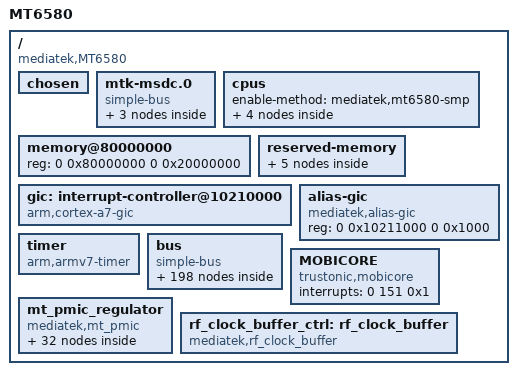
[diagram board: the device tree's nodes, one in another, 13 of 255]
/*
 * Mediatek's MT6580 SoC device tree source
 *
 * Copyright (c) 2013 MediaTek Co., Ltd.
 * http://www.mediatek.com
 *
 */

#include <dt-bindings/interrupt-controller/arm-gic.h>
#include <dt-bindings/interrupt-controller/irq.h>
#include "mt6580-pinfunc.h"
#include <dt-bindings/mmc/mt6580-msdc.h>

/ {
	model = "MT6580";
	compatible = "mediatek,MT6580";
	interrupt-parent = <&gic>;
	#address-cells = <2>;
	#size-cells = <2>;

		/* chosen */
		chosen {
		bootargs = "console=tty0 console=ttyMT0,921600n1 root=/dev/ram initrd=0x84000000,0x400000 loglevel=8";
		};

/* Do not put any bus before mtk-msdc, because it should be mtk-msdc.0 for partition device node usage */
		mtk-msdc.0 {
			compatible = "simple-bus";
			#address-cells = <1>;
			#size-cells = <1>;
			ranges = <0 0 0 0xffffffff>;

			mmc0: msdc0@11120000 {
				compatible = "mediatek,mt6580-mmc";
				reg = <0x11120000 0x10000/*MSDC0_BASE*/
					0x10001e84 0x2>;/*FPGA PWR_GPIO,PWR_GPIO_EO*/
				interrupts = <GIC_SPI 38 IRQ_TYPE_LEVEL_LOW>;
				status = "disabled";
				/* peter check when rainier ccf ready
				clocks = <&perisys PERI_MSDC30_0>,
					 <&topckgen TOP_MUX_MSDC30_0>,
					 <&topckgen TOP_MSDCPLL_CK>,
					 <&topckgen TOP_MSDCPLL_D2>,
					 <&topckgen TOP_MSDCPLL_D4>;
				clock-names="MSDC0-CLOCK",
					"MSDC0_PLL_SEL",
					"MSDC0_PLL_800M",
					"MSDC0_PLL_400M",
					"MSDC0_PLL_200M"; */
			};

			mmc1: msdc1@11130000 {
				compatible = "mediatek,mt6580-mmc";
				reg = <0x11130000 0x10000/*MSDC1_BASE*/
					0x10001e84 0x2>;/*FPGA PWR_GPIO,PWR_GPIO_EO*/
				interrupts = <GIC_SPI 39 IRQ_TYPE_LEVEL_LOW>;
				cd-gpios = <&pio 3 0>;
				status = "disabled";
				/* peter check when rainier ccf ready
				clocks = <&perisys PERI_MSDC30_1>;
				clock-names="MSDC1-CLOCK"; */
			};

			msdc1_ins: default {
				compatible = "mediatek,msdc1_ins-eint";
			};
		};

		cpus {
			#address-cells = <1>;
			#size-cells = <0>;
			enable-method = "mediatek,mt6580-smp";

			cpu0: cpu@0 {
				device_type = "cpu";
				compatible = "arm,cortex-a7";
				reg = <0x000>;
				clock-frequency = <1700000000>;
			};

			cpu1: cpu@1 {
				device_type = "cpu";
				compatible = "arm,cortex-a7";
				reg = <0x001>;
				clock-frequency = <1700000000>;
			};

			cpu2: cpu@2 {
				device_type = "cpu";
				compatible = "arm,cortex-a7";
				reg = <0x002>;
				clock-frequency = <1700000000>;
			};

			cpu3: cpu@3 {
				device_type = "cpu";
				compatible = "arm,cortex-a7";
				reg = <0x003>;
				clock-frequency = <1700000000>;
			};
		};

		memory@80000000 {
				device_type = "memory";
				reg = <0 0x80000000 0 0x20000000>;
		};

		reserved-memory {
				#address-cells = <2>;
				#size-cells = <2>;
				ranges;
				consys-reserve-memory {
					compatible = "mediatek,consys-reserve-memory";
					no-map;
					size = <0 0x200000>;
					alignment = <0 0x200000>;
				};
				reserve-memory-ccci_md1 {
						compatible = "mediatek,reserve-memory-ccci_md1";
						no-map;
						size = <0 0x1800000>; /* MD ROM + RAM + SMEM */
						alignment = <0 0x2000000>; /* 32M alignment */
						alloc-ranges = <0 0x80000000 0 0x80000000>;
				};

				pstore-reserved-memory@83f10000 {
						compatible = "mediatek,pstore";
						reg = <0 0x83f10000 0 0xe0000>;
				};

				ram_console-reserved-memory@83f00000 {
						compatible = "mediatek,ram_console";
						reg = <0 0x83f00000 0 0x10000>;
				};

				minirdump-reserved-memory@83ff0000 {
						compatible = "mediatek, minirdump";
						reg = <0 0x83ff0000 0 0x10000>;
				};
		};

		gic: interrupt-controller@10210000 {
				compatible = "arm,cortex-a7-gic";
				#interrupt-cells = <3>;
				#address-cells = <0>;
				interrupt-controller;
				reg = <0 0x10211000 0 0x1000>,
							<0 0x10212000 0 0x1000>,
							<0 0x10200100 0 0x1000>;
			 interrupts = <1 9 0xf04>;
		};

		/* redundent gic device node to support other module's
			who want to use same query flow to get basic GIC info.
			EX: eint might want to know max GIC nr by */
		alias-gic {
			compatible = "mediatek,alias-gic";
			reg = <0 0x10211000 0 0x1000>; /* only dist base is enough */
		};

		timer {
				compatible = "arm,armv7-timer";
				interrupts = <1 13 0x8>,
				<1 14 0x8>,
				<1 11 0x8>,
				<1 10 0x8>;
				clock-frequency = <13000000>;
		};

	bus {
		compatible = "simple-bus";
		#address-cells = <1>;
		#size-cells = <1>;
		ranges = <0 0 0 0xffffffff>;

		chipid@08000000 {
			compatible = "mediatek,chipid";
			reg = <0x08000000 0x0004>,
					<0x08000004 0x0004>,
					<0x08000008 0x0004>,
					<0x0800000C 0x0004>;
		};

		TOPCKGEN@0x10000000 {
			compatible = "mediatek,TOPCKGEN";
			reg = <0x10000000 0x1000>;
		};

		INFRACFG_AO@0x10001000 {
			compatible = "mediatek,INFRACFG_AO";
			reg = <0x10001000 0x1000>;
		};

		bat_meter: bat_meter {
			compatible = "mediatek,bat_meter";
		};

		BAT_NOTIFY {
			compatible = "mediatek,bat_notify";
		};

		bat_comm: bat_comm {
			compatible = "mediatek,battery";
		};

		keypad: keypad@10002000 {
			compatible = "mediatek,mt6580-keypad";
			reg = <0x10002000 0x1000>;
			interrupts = <0 109 0x2>;
		};

		PERICFG@0x10003000 {
			compatible = "mediatek,PERICFG";
			reg = <0x10003000 0x1000>;
		};

		RESERVED@0x10004000 {
			compatible = "mediatek,RESERVED";
			reg = <0x10004000 0x1000>;
		};

		gpio_usage_mapping:gpio {
			compatible = "mediatek,gpio_usage_mapping";
		};

		gpio: gpio@0x10005000 {
			compatible = "mediatek,gpio";
			reg = <0x10005000 0x1000>;
		};

		SLEEP@0x10006000 {
			compatible = "mediatek,SLEEP";
			reg = <0x10006000 0x1000>;
			interrupts = <0 88 0x8>,
						 <0 89 0x8>,
						 <0 90 0x8>,
						 <0 91 0x8>;
		};

		TOPRGU@0x10007000 {
			compatible = "mediatek,TOPRGU";
			reg = <0x10007000 0x1000>;
			interrupts = <0 157 0x2>;
		};

		APXGPT@0x10008000 {
			compatible = "mediatek,APXGPT";
			reg = <0x10008000 0x1000>;
			interrupts = <0 92 0x8>;
			clock-frequency = <13000000>;
		};

		EFUSEC@0x10009000 {
			compatible = "mediatek,EFUSEC";
			reg = <0x10009000 0x1000>;
		};

		hacc@0x1000A000 {
			compatible = "mediatek,hacc";
			reg = <0x1000A000 0x1000>;
			interrupts = <0 110 0x0>;
		};

		cpu_dbgapb: cpu_dbgapb@10170000 {
			compatible = "mediatek,mt6580-dbg_debug";
			num = <4>;
			reg = <0x10170000 0x2000
				0x10172000 0x2000
				0x10174000 0x2000
				0x10176000 0x2000>;
		};

		eintc: eintc@1000b000 {
			compatible = "mediatek,mt-eic";
			reg = <0x1000B000 0x1000>;
			interrupts = <GIC_SPI 94 IRQ_TYPE_LEVEL_HIGH>;

			#interrupt-cells = <2>;
			interrupt-controller;

			mediatek,max_eint_num = <26>;
			mediatek,mapping_table_entry = <83>;
			mediatek,mapping_table = <0 0>, /* <gpio_pin, eint_pin> */
					<1 1>,
					<2 2>,
					<3 3>,
					<4 4>,
					<5 5>,
					<6 6>,
					<7 7>,
					<8 8>,
					<9 9>,
					<10 10>,
					<11 11>,
					<12 12>,
					<13 13>,
					<14 14>,
					<15 15>,
					<16 0>,
					<17 1>,
					<18 2>,
					<19 3>,
					<20 4>,
					<21 5>,
					<22 6>,
					<23 7>,
					<24 8>,
					<25 9>,
					<26 10>,
					<27 11>,
					<28 12>,
					<29 13>,
					<30 14>,
					<31 15>,
					<32 0>,
					<33 1>,
					<34 2>,
					<35 3>,
					<36 4>,
					<37 5>,
					<38 6>,
					<39 7>,
					<40 8>,
					<41 9>,
					<42 10>,
					<43 11>,
					<44 12>,
					<45 13>,
					<46 14>,
					<47 15>,
					<48 0>,
					<49 1>,
					<50 2>,
					<51 3>,
					<52 3>,
					<53 4>,
					<54 5>,
					<55 6>,
					<56 7>,
					<57 8>,
					<58 10>,
					<59 11>,
					<60 12>,
					<61 13>,
					<62 14>,
					<63 15>,
					<64 0>,
					<65 1>,
					<66 2>,
					<67 3>,
					<68 16>,
					<69 4>,
					<70 5>,
					<71 6>,
					<72 7>,
					<73 8>,
					<74 9>,
					<75 10>,
					<76 11>,
					<77 12>,
					<78 13>,
					<81 0>,
					<82 1>,
					<83 2>,
					<84 3>;

			/* the number of gpio/eint mapping might be affected by built-in eint */
			mediatek,builtin_entry = <11>;
			/* gpio, built-in func mode, built-in eint */
			mediatek,builtin_mapping = <0 3 20>, /* USB IDDIG & USB VBUS */
						 <1 3 18>,
						 <7 4 20>,
						 <8 4 18>,
						 <9 3 20>,
						 <10 3 18>,
						 <24 5 20>,
						 <25 5 18>,
						 <77 2 20>,
						 <78 2 18>,
						 <13 1 17>; /* PMIC */
		};

		ap_ccif0:ap_ccif0@1000C000 {
			compatible = "mediatek,ap_ccif0";
			reg =	<0x1000C000 0x1000>,	/*AP_CCIF_BASE*/
				<0x1000D000 0x1000>;	/*MD_CCIF_BASE*/
			interrupts =	<GIC_SPI 93 IRQ_TYPE_LEVEL_LOW>, /* CCIF0 IRQ */
					<GIC_SPI 152 IRQ_TYPE_EDGE_FALLING>;/* MD WDT IRQ */
			mediatek,ccif_capability = <2>;
			mediatek,md_smem_size = <0x200000>; /* md share memory size */
		};

		MCUSYS_CFGREG@0x1020000 {
			compatible = "mediatek,MCUSYS_CFGREG_BASE";
			reg = <0x1020000 0x200>;
		};

		mcucfg: mcucfg@10200000 {
			compatible = "mediatek,mt6580-mcucfg";
			reg = <0x10200000 0x200>;
		};

		AES@0x1000E000 {
			compatible = "mediatek,AES";
			reg = <0x1000E000 0x1000>;
		};

		PWRAP@0x1000F000 {
			compatible = "mediatek,PWRAP";
			reg = <0x1000F000 0x1000>;
			interrupts = <0 108 0x0>;
		};

		DEVAPC_AO@0x10010000 {
			compatible = "mediatek,DEVAPC_AO";
			reg = <0x10010000 0x1000>;
		};

		MIPI_CONFG@0x10011000 {
			compatible = "mediatek,MIPI_CONFG";
			reg = <0x10011000 0x1000>;
		};

		INFRA_MBIST@0x10012000 {
			compatible = "mediatek,INFRA_MBIST";
			reg = <0x10012000 0x1000>;
		};

		RESERVED@0x10013000 {
			compatible = "mediatek,RESERVED";
			reg = <0x10013000 0x1000>;
		};

		IOCFG_T@0x10014000 {
			compatible = "mediatek,IOCFG_T";
			reg = <0x10014000 0x1000>;
		};

		IOCFG_B@0x10015000 {
			compatible = "mediatek,IOCFG_B";
			reg = <0x10015000 0x1000>;
		};

		IOCFG_L@0x10016000 {
			compatible = "mediatek,IOCFG_L";
			reg = <0x10016000 0x1000>;
		};

		IOCFG_R@0x10017000 {
			compatible = "mediatek,IOCFG_R";
			reg = <0x10017000 0x1000>;
		};

		APMIXED@0x10018000 {
			compatible = "mediatek,APMIXED";
			reg = <0x10018000 0x1000>;
		};

		MCUCFG@0x10200000 {
			compatible = "mediatek,MCUCFG";
			reg = <0x10200000 0x1000>;
		};

		INFRACFG@0x10201000 {
			compatible = "mediatek,INFRACFG";
			reg = <0x10201000 0x1000>;
		};

		sys_cirq: sys_cirq@10202000 {
			compatible = "mediatek,mt6580-sys_cirq", "mediatek,mt6735-sys_cirq";
			reg = <0x10202000 0x1000>;
			interrupts = <GIC_SPI 158 IRQ_TYPE_LEVEL_LOW>;
			mediatek,cirq_num = <126>;
			mediatek,spi_start_offset = <32>;
		};


		m4u@10203000 {
			cell-index = <0>;
			compatible = "mediatek,m4u";
			reg = <0x10203000 0x1000>;
			interrupts =  <GIC_SPI 81 IRQ_TYPE_LEVEL_LOW>;
		};

		DEVAPC@0x10204000 {
			compatible = "mediatek,DEVAPC";
			reg = <0x10204000 0x1000>;
			interrupts = <0 74 0x8>;
		};

		EMI@0x10205000 {
			compatible = "mediatek,EMI";
			reg = <0x10205000 0x1000>;
			interrupts = <0 76 0x4>;
		};

		DRAMC_NAO@0x10206000 {
			compatible = "mediatek,DRAMC_NAO";
			reg = <0x10206000 0x1000>;
		};

		DRAMC0@0x10207000 {
			compatible = "mediatek,DRAMC0";
			reg = <0x10207000 0x1000>;
		};

		DDRPHY@0x10208000 {
			compatible = "mediatek,DDRPHY";
			reg = <0x10208000 0x1000>;
		};

		SRAMROM@0x10209000 {
			compatible = "mediatek,SRAMROM";
			reg = <0x10209000 0x1000>;
		};

		gce@1020a000 {
			compatible = "mediatek,gce";
			reg = <0x1020a000 0x1000>;
			interrupts = <GIC_SPI 85 IRQ_TYPE_LEVEL_LOW>,
						<GIC_SPI 86 IRQ_TYPE_LEVEL_LOW>;
			disp_mutex_reg = <0x14015000 0x1000>;
			g3d_config_base = <0x13000000 0 0xffff0000>;
			mmsys_config_base = <0x14000000 1 0xffff0000>;
			disp_dither_base = <0x14010000 2 0xffff0000>;
			mm_na_base = <0x14020000 3 0xffff0000>;
			imgsys_base = <0x15000000 4 0xffff0000>;
			vdec_gcon_base = <0x16000000 5 0xffff0000>;
			venc_gcon_base = <0x17000000 6 0xffff0000>;
			conn_peri_base = <0x18000000 7 0xffff0000>;
			topckgen_base = <0x10000000 8 0xffff0000>;
			kp_base = <0x10010000 9 0xffff0000>;
			scp_sram_base = <0x10020000 10 0xffff0000>;
			infra_na3_base = <0x10030000 11 0xffff0000>;
			infra_na4_base = <0x10040000 12 0xffff0000>;
			scp_base = <0x10050000 13 0xffff0000>;
			mcucfg_base = <0x10200000 14 0xffff0000>;
			gcpu_base = <0x10210000 15 0xffff0000>;
			usb0_base = <0x11200000 16 0xffff0000>;
			usb_sif_base = <0x11210000 17 0xffff0000>;
			audio_base = <0x11220000 18 0xffff0000>;
			msdc0_base = <0x11230000 19 0xffff0000>;
			msdc1_base = <0x11240000 20 0xffff0000>;
			msdc2_base = <0x11250000 21 0xffff0000>;
			msdc3_base = <0x11260000 22 0xffff0000>;
			pwm_sw_base = <0x1100F000 99 0xfffff000>;
			mdp_rdma0_sof = <0>;
			mdp_rsz0_sof = <1>;
			mdp_rsz1_sof = <2>;
			mdp_tdshp_sof = <3>;
			mdp_wdma_sof = <4>;
			mdp_wrot_sof = <5>;
			disp_ovl0_sof = <6>;
			disp_rdma0_sof = <8>;
			disp_wdma0_sof = <10>;
			disp_color_sof = <12>;
			disp_aal_sof = <13>;
			disp_gamma_sof = <14>;
			disp_dither_sof = <15>;
			disp_pwm0_sof = <17>;
			mdp_rdma0_frame_done = <18>;
			mdp_rsz0_frame_done = <19>;
			mdp_rsz1_frame_done = <20>;
			mdp_tdshp_frame_done = <21>;
			mdp_wdma_frame_done = <22>;
			mdp_wrot_write_frame_done = <23>;
			mdp_wrot_read_frame_done = <24>;
			disp_ovl0_frame_done = <25>;
			disp_rdma0_frame_done = <27>;
			disp_wdma0_frame_done = <29>;
			disp_color_frame_done = <31>;
			disp_aal_frame_done = <32>;
			disp_gamma_frame_done = <33>;
			disp_dither_frame_done = <34>;
			disp_dsi0_frame_done = <37>;
			stream_done_0 = <38>;
			stream_done_1 = <39>;
			stream_done_2 = <40>;
			stream_done_3 = <41>;
			stream_done_4 = <42>;
			stream_done_5 = <43>;
			stream_done_6 = <44>;
			stream_done_7 = <45>;
			stream_done_8 = <46>;
			stream_done_9 = <47>;
			buf_underrun_event_0 = <48>;
			dsi0_te_event = <50>;
			isp_frame_done_p2_1 = <66>;
			isp_frame_done_p2_0 = <67>;
			seninf_cam0_fifo_full = <73>;
			apxgpt2_count = <0x10008028>;
		};

		bus_dbg@1020b000 {
			compatible = "mediatek,bus_dbg-v2";
			reg = <0x1020b000 0x1000>;
			interrupts = <GIC_SPI 73 IRQ_TYPE_LEVEL_LOW>;
			two_stage_timeout = <1>;
		};

		TRNG@0x1020C000 {
			compatible = "mediatek,TRNG";
			reg = <0x1020C000 0x1000>;
			interrupts = <0 87 0x8>;
		};

		MCUCFG_BIU@0x1020D000 {
			compatible = "mediatek,MCUCFG_BIU";
			reg = <0x1020D000 0x1000>;
		};


		DBGSYS_DEM@0x1011A000 {
			compatible = "mediatek,DBGSYS_DEM";
			reg = <0x1011A000 0x1000>;
		};

		DBGSYS_CTI@0x10112000 {
			compatible = "mediatek,DBGSYS_CTI";
			reg = <0x10112000 0x1000>;
		};

		DBGSYS_DAPROM@0x10110000 {
			compatible = "mediatek,DBGSYS_DAPROM";
			reg = <0x10110000 0x1000>;
		};

		DBGSYS_CPU@0x10160000 {
			compatible = "mediatek,DBGSYS_CPU";
			reg = <0x10160000 0x20000>;
		};

		DBGSYS_MDSYS@0x10120000 {
			compatible = "mediatek,DBGSYS_MDSYS";
			reg = <0x10120000 0x10000>;
		};

		ap_dma: dma@0x11000000 {
			compatible = "mediatek,ap_dma";
			reg = <0x11000000 0x1000>;
			interrupts = <GIC_SPI 48 IRQ_TYPE_LEVEL_LOW>;
		};

		NFI@0x11001000 {
			compatible = "mediatek,NFI";
			reg = <0x11001000 0x1000>;
			interrupts = <0 47 0x8>;
		};

		NFIECC@0x11002000 {
			compatible = "mediatek,NFIECC";
			reg = <0x11002000 0x1000>;
			interrupts = <0 46 0x8>;
		};

		auxadc: adc_hw@11003000 {
			compatible = "mediatek,mt6735-auxadc";
			reg = <0x11003000 0x1000>;
			interrupts = <GIC_SPI 35 IRQ_TYPE_EDGE_FALLING>;
		};

		FHCTL@0x11004000 {
			compatible = "mediatek,FHCTL";
			reg = <0x11004000 0x1000>;
		};

		AP_UART0@0x11005000 {
			cell-index = <0>;
			compatible = "mediatek,AP_UART0";
			reg = <0x11005000 0x1000>;
			interrupts = <0 44 0x8>;
		};

		AP_UART1@0x11006000 {
			cell-index = <1>;
			compatible = "mediatek,AP_UART1";
			reg = <0x11006000 0x1000>;
			interrupts = <0 45 0x8>;
		};

		AP_DMA_UART0_TX@0x11000480 {
			compatible = "mediatek,AP_DMA_UART0_TX";
			reg = <0x11000480 0x80>;
			interrupts = <0 56 0x8>;
		};

		AP_DMA_UART0_RX@0x11000500 {
			compatible = "mediatek,AP_DMA_UART0_RX";
			reg = <0x11000500 0x80>;
			interrupts = <0 57 0x8>;
		};

				AP_DMA_UART1_TX@0x11000580 {
						compatible = "mediatek,AP_DMA_UART1_TX";
						reg = <0x11000580 0x80>;
						interrupts = <0 58 0x8>;
				};

				AP_DMA_UART1_RX@0x11000600 {
						compatible = "mediatek,AP_DMA_UART1_RX";
						reg = <0x11000600 0x80>;
						interrupts = <0 59 0x8>;
				};


		PWM@0x11008000 {
			compatible = "mediatek,PWM";
			reg = <0x11008000 0x1000>;
			interrupts = <0 36 0x8>;
		};

		syscfg_pctl_a: syscfg_pctl_a@0x10005000 {
			compatible = "mediatek,mt6580-pctl-a-syscfg", "syscon";
			reg = <0x10211000 0x1000>;
		};

		pio: pinctrl@0x10005000 {
			compatible = "mediatek,mt6580-pinctrl";
			reg = <0x10005000 0x1000>;
			mediatek,pctl-regmap = <&syscfg_pctl_a>;
			pins-are-numbered;
			gpio-controller;
			#gpio-cells = <2>;
		};
		i2c0: i2c@11009000 {
			compatible = "mediatek,mt6580-i2c", "mediatek,i2c0";
			cell-index = <0>;
			reg = <0x11009000 0x1000>;
			interrupts = <GIC_SPI 40 IRQ_TYPE_LEVEL_LOW>,
				     <GIC_SPI 50 IRQ_TYPE_LEVEL_LOW>;
			clock-div = <10>;
			#address-cells = <1>;
			#size-cells = <0>;
		};

		i2c1: i2c@1100a000 {
			compatible = "mediatek,mt6580-i2c", "mediatek,i2c1";
			cell-index = <1>;
			reg = <0x1100a000 0x1000>;
			interrupts = <GIC_SPI 41 IRQ_TYPE_LEVEL_LOW>,
				     <GIC_SPI 51 IRQ_TYPE_LEVEL_LOW>;
			clock-div = <10>;
			#address-cells = <1>;
			#size-cells = <0>;
		};

		i2c2: i2c@1100b000 {
			compatible = "mediatek,mt6580-i2c", "mediatek,i2c2";
			cell-index = <2>;
			reg = <0x1100b000 0x1000>;
			interrupts = <GIC_SPI 42 IRQ_TYPE_LEVEL_LOW>,
				     <GIC_SPI 52 IRQ_TYPE_LEVEL_LOW>;
			clock-div = <10>;
			#address-cells = <1>;
			#size-cells = <0>;
		};

		touch: touch@0 {
			compatible = "mediatek,mt6580-touch";
			vtouch-supply = <&mt_pmic_vgp1_ldo_reg>;
		};
		accdet: accdet {
			compatible = "mediatek,mt6580-accdet";
		};

		gse_1: gse_1 {
			compatible = "mediatek, gse_1-eint";
			status = "disabled";
		};

		spi@1100c000 {
			compatible = "mediatek,mt6580-spi";
			cell-index = <0>;
			reg = <0x1100c000 0x1000>;
			interrupts = <GIC_SPI 64 IRQ_TYPE_LEVEL_LOW>;
			mediatek,spi-padmacro = <0>;
		};

		THERM_CTRL@0x1100D000 {
			compatible = "mediatek,THERM_CTRL";
			reg = <0x1100D000 0x1000>;
			interrupts = <0 37 0x8>;
		};


		btif_tx:btif_tx@11000380 {
			compatible = "mediatek,btif_tx";
			reg = <0x11000380 0x80>;
			interrupts = <GIC_SPI 54 IRQ_TYPE_LEVEL_LOW>;
		};

		btif_rx:btif_rx@11000400 {
			compatible = "mediatek,btif_rx";
			reg = <0x11000400 0x80>;
			interrupts = <GIC_SPI 55 IRQ_TYPE_LEVEL_LOW>;
		};

		btif:btif@1100e000 {
			compatible = "mediatek,btif";
			reg = <0x1100e000 0x1000>;
			interrupts = <GIC_SPI 67 IRQ_TYPE_LEVEL_LOW>;
			/*clocks = <&perisys PERI_BTIF>,<&perisys PERI_APDMA>;*/
			/*clock-names = "btifc","apdmac";*/
		};/* End of btif */

		mt3326-gps@0xffffffff {
			compatible = "mediatek,mt3326-gps";
		};


		BTCVSD@0x18000000 {
			compatible = "mediatek,audio_bt_cvsd";
		/*INFRA MISC, conn_bt_cvsd_mask, cvsd_mcu_read, write, packet_indicator*/
			offset =<0xC00 0x2 0xFD0 0xFD4 0xFD8>;
			reg=<0x10001000 0x1000>, /*AUDIO_INFRA_BASE_PHYSICAL*/
						<0x18000000 0x10000>, /*PKV_PHYSICAL_BASE*/
						<0x18080000 0x8000>; /*SRAM_BANK2*/
			interrupts = <0 153 0x8>;
		};

		consys:consys@18070000 {
			compatible = "mediatek,mt6580-consys";
			reg =	<0x18070000 0x0200>,	/*CONN_MCU_CONFIG_BASE*/
				<0x10007000 0x0100>,	/*AP_RGU_BASE*/
				<0x10000000 0x2000>,	/*TOPCKGEN_BASE*/
				<0x10006000 0x1000>,	/*SPM_BASE*/
				<0x10005000 0x1000>;	/*DA_XOBUF*/
			interrupts = <GIC_SPI 154 IRQ_TYPE_LEVEL_LOW>, /*BGF_EINT*/
					<GIC_SPI 156 IRQ_TYPE_LEVEL_LOW>; /*WDT_EINT*/
			/*clocks = <&scpsys SCP_SYS_CONN>,<&infrasys INFRA_CONNMCU_BUS>;*/
			/*clock-names = "conn","bus";*/
			vcn18-supply = <&mt_pmic_vcn_1v8_ldo_reg>;
			vcn28-supply = <&mt_pmic_vcn28_ldo_reg>;
			vcn33_bt-supply = <&mt_pmic_vcn33_bt_ldo_reg>;
			vcn33_wifi-supply = <&mt_pmic_vcn33_wifi_ldo_reg>;
		};

		WIFI@0x180F0000 {
			compatible = "mediatek,WIFI";
			reg = <0x180F0000 0x005C>;
			interrupts = <0 155 0x8>;
		};
		DISP_PWM@0x1100F000 {
			compatible = "mediatek,DISP_PWM";
			reg = <0x1100F000 0x1000>;
			interrupts = <0 33 0x8>;
		};

		usb0:USB0@0x11100000 {
			compatible = "mediatek,USB0";
			cell-index = <0>;
			reg = <0x11100000 0x10000>,
						<0x11110000 0x10000>;
			interrupts = <0 32 0x8>;
			mode = <2>;
			multipoint = <1>;
			dyn_fifo = <1>;
			soft_con = <1>;
			dma = <1>;
			num_eps = <16>;
			dma_channels = <8>;
			iddig_gpio = <9 3>;
			drvvbus_gpio = <10 3>;
			usbiddig:usbiddig {
				compatible = "mediatek,usb_iddig_eint";
			};
		};

		usbphy0: usbphy@0 {
			compatible = "usb-nop-xceiv";
		};

		audio@11140000 {
			compatible = "mediatek,audio";
			reg = <0x11140000 0x10000>;
			interrupts = <0 80 0x8>;
		};

		audgpio:mt_soc_dl1_pcm@11140000 {
			compatible = "mediatek,mt_soc_pcm_dl1";
			reg = <0x11140000 0x1000>;
			interrupts = <0 80 0x8>;
			audclk-gpio = <26 0>;
			audmiso-gpio = <28 0>;
			audmosi-gpio = <27 0>;
		};

		mt_soc_ul1_PCM@11140000 {
			compatible = "mediatek,mt_soc_pcm_capture";
		};

		mt_soc_voice_md1@11140000 {
			compatible = "mediatek,mt_soc_pcm_voice_md1";
		};

		mt_soc_hdmi_pcm@11140000 {
			compatible = "mediatek,mt_soc_pcm_hdmi";
		};

		mt_soc_uldlloopback_pcm@11140000 {
			compatible = "mediatek,mt_soc_pcm_uldlloopback";
		};

		mt_soc_i2s0_pcm@11140000 {
			compatible = "mediatek,mt_soc_pcm_dl1_i2s0";
		};

		mt_soc_mrgrx_pcm@11140000 {
			compatible = "mediatek,mt_soc_pcm_mrgrx";
		};

		mt_soc_mrgrx_awb_pcm@11140000 {
			compatible = "mediatek,mt_soc_pcm_mrgrx_awb";
		};

		mt_soc_fm_i2s_pcm@0x11140000 {
			compatible = "mediatek,mt_soc_pcm_fm_i2s";
		};

		mt_soc_fm_i2s_awb_pcm@11140000 {
			compatible = "mediatek,mt_soc_pcm_fm_i2s_awb";
		};

		mt_soc_i2s0dl1_pcm@11140000 {
			compatible = "mediatek,mt_soc_pcm_dl1_i2s0Dl1";
		};

		mt_soc_dl1_awb_pcm@11140000 {
			compatible = "mediatek,mt_soc_pcm_dl1_awb";
		};

		mt_soc_voice_md1_bt@11140000 {
			compatible = "mediatek,mt_soc_pcm_voice_md1_bt";
		};

		mt_soc_voip_bt_out@11140000 {
			compatible = "mediatek,mt_soc_pcm_dl1_bt";
		};

		mt_soc_voip_bt_in@11140000 {
			compatible = "mediatek,mt_soc_pcm_bt_dai";
		};

		mt_soc_tdmrx_pcm@11140000 {
			compatible = "mediatek,mt_soc_tdm_capture";
		};

		mt_soc_fm_mrgtx_pcm@11140000 {
			compatible = "mediatek,mt_soc_pcm_fmtx";
		};

		mt_soc_ul2_pcm@11140000 {
			compatible = "mediatek,mt_soc_pcm_capture2";
		};

		mt_soc_i2s0_awb_pcm@11140000 {
			compatible = "mediatek,mt_soc_pcm_i2s0_awb";
		};

		mt_soc_voice_md2@11140000 {
			compatible = "mediatek,mt_soc_pcm_voice_md2";
		};

		mt_soc_routing_pcm@11140000 {
			compatible = "mediatek,mt_soc_pcm_routing";
		};

		mt_soc_voice_md2_bt@11140000 {
			compatible = "mediatek,mt_soc_pcm_voice_md2_bt";
		};

		mt_soc_hp_impedance_pcm@11140000 {
			compatible = "mediatek,Mt_soc_pcm_hp_impedance";
		};

		mt_soc_codec_name@11140000 {
			compatible = "mediatek,mt_soc_codec_63xx";
		};

		mt_soc_dummy_pcm@11140000 {
			compatible = "mediatek,mt_soc_pcm_dummy";
		};

		mt_soc_codec_dummy_name@11140000 {
			compatible = "mediatek,mt_soc_codec_dummy";
		};

		mt_soc_routing_dai_name@11140000 {
			compatible = "mediatek,mt_soc_dai_routing";
		};

		mt_soc_dai_name@11140000 {
			compatible = "mediatek,mt_soc_dai_stub";
		};

		mt_soc_dl2_pcm@11140000 {
			compatible = "mediatek,mt_soc_pcm_dl2";
		};

		AHB_MOM@0x11150000 {
			compatible = "mediatek,AHB_MOM";
			reg = <0x11150000 0x10000>;
		};

		MDI@0x11160000 {
			compatible = "mediatek,MDI";
			reg = <0x11160000 0x10000>;
		};

		G3D_CONFIG@0x13000000 {
			compatible = "mediatek,G3D_CONFIG";
			reg = <0x13000000 0x1000>;
		};

		MALI@0x13010000 {
			compatible = "mediatek,MALI";
			reg = <0x13010000 0x10000>;
		};

		mmsys_config@14000000 {
			compatible = "mediatek,mmsys_config";
			reg = <0x14000000 0x1000>;
			interrupts = <GIC_SPI 132 IRQ_TYPE_LEVEL_LOW>;
		};

		mdp_rdma@14001000 {
			compatible = "mediatek,mdp_rdma";
			reg = <0x14001000 0x1000>;
			interrupts = <GIC_SPI 113 IRQ_TYPE_LEVEL_LOW>;
		};

		mdp_rsz0@14002000 {
			compatible = "mediatek,mdp_rsz0";
			reg = <0x14002000 0x1000>;
			interrupts = <GIC_SPI 114 IRQ_TYPE_LEVEL_LOW>;
		};

		mdp_rsz1@14003000 {
			compatible = "mediatek,mdp_rsz1";
			reg = <0x14003000 0x1000>;
			interrupts = <GIC_SPI 115 IRQ_TYPE_LEVEL_LOW>;
		};

		mdp_wdma@14004000 {
			compatible = "mediatek,mdp_wdma";
			reg = <0x14004000 0x1000>;
			interrupts = <GIC_SPI 117 IRQ_TYPE_LEVEL_LOW>;
		};

		mdp_wrot@14005000 {
			compatible = "mediatek,mdp_wrot";
			reg = <0x14005000 0x1000>;
			interrupts = <GIC_SPI 118 IRQ_TYPE_LEVEL_LOW>;
		};

		mdp_tdshp@14006000 {
			compatible = "mediatek,mdp_tdshp";
			reg = <0x14006000 0x1000>;
			interrupts = <GIC_SPI 116 IRQ_TYPE_LEVEL_LOW>;
		};

		lcm: lcm {
			compatible = "mediatek,mt6580-lcm";
		};

		DISPSYS@0x14007000 {
			compatible = "mediatek,DISPSYS";
			reg = <0x14000000 0x1000>,/*DISP_SYS */
			<0x14007000 0x1000>,	/*DISP_OVL0*/
			<0x14008000 0x1000>,	/*DISP_OVL1*/
			<0x14009000 0x1000>,	/*DISP_RDMA0*/
			<0x1400A000 0x1000>,	/*DISP_RDMA1*/
			<0x1400B000 0x1000>,	/*DISP_WDMA0*/
			<0x1400C000 0x1000>,	/*DISP_COLOR*/
			<0x1400D000 0x1000>,	/*DISP_CCORR*/
			<0x1400E000 0x1000>,	/*DISP_AAL*/
			<0x1400F000 0x1000>,	/*DISP_GAMMA*/
			<0x14010000 0x1000>,	/*DISP_DITHER*/
			<0x14011000 0x1000>,	/*DISP_UFOE*/
			<0x14012000 0x1000>,	/*DISP_DSI0*/
			<0x14013000 0x1000>,	/*DISP_DPI0*/
			<0x1100F000 0x1000>,	/*DISP_PWM*/
			<0x14015000 0x1000>,	/*DISP_MUTEX*/
			<0x14016000 0x1000>,	/*DISP_SMI_LARB0 */
			<0x14017000 0x1000>,	/*DISP_SMI_COMMOM*/
			<0x14018000 0x1000>;	/*MIPITX0,real chip would use this*/

			interrupts = <0 0 8>, /*DISP_SYS */
									<0 119 8>, /*DISP_OVL0 */
									<0 0 8>, /*DISP_OVL1 */
									<0 121 8>, /*DISP_RDMA0 */
									<0 0 8>, /*DISP_RDMA1 */
									<0 123 8>, /*DISP_WDMA0 */
									<0 124 8>, /*DISP_COLOR */
									<0 0 8>, /*DISP_CCORR */
									<0 126 8>, /*DISP_AAL */
									<0 127 8>, /*DISP_GAMMA */
									<0 128 8>, /*DISP_DITHER */
									<0 0 8>, /*DISP_UFOE */
									<0 130 8>, /*DISP_DSI0 */
									<0 0 8>, /*DISP_DPI0 */
									<0 0 8>, /*DISP_PWM */
									<0 112 8>, /*DISP_MUTEX */
									<0 0 8>, /*DISP_SMI_LARB0 */
									<0 0 8>, /*DISP_SMI_COMMOM*/
									<0 0 8>; /*MIPITX0*/
					};

		DISP_OVL0@0x14007000 {
			compatible = "mediatek,DISP_OVL0";
			reg = <0x14007000 0x1000>;
			interrupts = <0 119 0x8>;
		};

		DISP_OVL1@0x14008000 {
			compatible = "mediatek,DISP_OVL1";
			reg = <0x14008000 0x1000>;
		};

		DISP_RDMA0@0x14009000 {
			compatible = "mediatek,DISP_RDMA0";
			reg = <0x14009000 0x1000>;
			interrupts = <0 121 0x8>;
		};

		DISP_RDMA1@0x1400A000 {
			compatible = "mediatek,DISP_RDMA1";
			reg = <0x1400A000 0x1000>;
		};

		DISP_WDMA@0x1400B000 {
			compatible = "mediatek,DISP_WDMA";
			reg = <0x1400B000 0x1000>;
			interrupts = <0 123 0x8>;
		};

		DISP_COLOR@0x1400C000 {
			compatible = "mediatek,DISP_COLOR";
			reg = <0x1400C000 0x1000>;
			interrupts = <0 124 0x8>;
		};

		DISP_CCORR@0x1400D000 {
			compatible = "mediatek,DISP_CCORR";
			reg = <0x1400D000 0x1000>;
		};

		DISP_AAL@0x1400E000 {
			compatible = "mediatek,DISP_AAL";
			reg = <0x1400E000 0x1000>;
			interrupts = <0 126 0x8>;
		};

		DISP_GAMMA@0x1400F000 {
			compatible = "mediatek,DISP_GAMMA";
			reg = <0x1400F000 0x1000>;
			interrupts = <0 127 0x8>;
		};

		DISP_DITHER@0x14010000 {
			compatible = "mediatek,DISP_DITHER";
			reg = <0x14010000 0x1000>;
			interrupts = <0 128 0x8>;
		};

		DISP_UFOE@0x14011000 {
			compatible = "mediatek,DISP_UFOE";
			reg = <0x14011000 0x1000>;
		};

		DSI@0x14012000 {
			compatible = "mediatek,DSI";
			reg = <0x14012000 0x1000>;
		};

		DPI@0x14013000 {
			compatible = "mediatek,DPI";
			reg = <0x14013000 0x1000>;
		};


		PTP_FSM@0x1100D000 {
			compatible = "mediatek,PTP_FSM";
			reg = <0x1100D000 0x1000>;
			interrupts = <0 43 0x8>;
		};

		MM_MUTEX@0x14015000 {
			compatible = "mediatek,MM_MUTEX";
			reg = <0x14015000 0x1000>;
			interrupts = <0 112 0x8>;
		};

		SMI_LARB0@0x14016000 {
			compatible = "mediatek,SMI_LARB0";
			reg = <0x14016000 0x1000>;
			interrupts = <0 133 0x8>;
		};

		SMI_COMMON@0x14017000 {
			compatible = "mediatek,SMI_COMMON";
			reg = <0x14017000 0x1000>,/* SMI_COMMON */
				<0x14016000 0x1000>,/* LARB 0 */
				<0x15001000 0x1000>;/* LARB 1 */
		};

		MIPI_TX_CONFIG@0x14018000 {
			compatible = "mediatek,MIPI_TX_CONFIG";
			reg = <0x14018000 0x1000>;
		};

		ISPSYS@0x15000000 {
			compatible = "mediatek,ISPSYS";
			reg = <0x15004000 0x9000>,	/*ISP_ADDR*/
				<0x15000000 0x10000>,	/*IMGSYS_CONFIG_ADDR*/
				<0x10011000 0x4000>,	/*MIPI_ANA_ADDR*/
				<0x10017000 0x1000>;
			interrupts = <0 142 0x8>, /* SENINF */
				<0 139 0x8>; /* CAM0 */
		};
		/*for sysram dev and pipemgr dev*/
		ISP_SYSR@0x15000000 {
			compatible = "mediatek,ISP_SYSR";
		};
		ISP_PIPEM@0x15000000 {
			compatible = "mediatek,ISP_PIPEM";
		};
		kd_camera_hw1:kd_camera_hw1@15008000 {
			compatible = "mediatek,camera_hw";
			reg = <0x15008000 0x1000>;  /* SENINF_ADDR */
			vcama-supply = <&mt_pmic_vcama_ldo_reg>;
			vcamd-supply = <&mt_pmic_vcamd_ldo_reg>;
			vcamaf-supply = <&mt_pmic_vcamaf_ldo_reg>;
			vcamio-supply = <&mt_pmic_vcamio_ldo_reg>;

		};
		kd_camera_hw2:kd_camera_hw2@15008000 {
			compatible = "mediatek,camera_hw2";
			reg = <0x15008000 0x1000>;  /* SENINF_ADDR */
		};
		seninf_top@15008000 {
			compatible = "mediatek,SENINF_TOP";
			reg = <0x15008000 0x1000>;
			interrupts = <0 142 0x8>;
		};

		CAM_0@0x15004000 {
			compatible = "mediatek,CAM_0";
			reg = <0x15004000 0x1000>;
			interrupts = <0 139 0x8>;
		};

		CAM_1@0x15005000 {
			compatible = "mediatek,CAM_1";
			reg = <0x15005000 0x1000>;
		};

		VENC@0x15009000 {
			compatible = "mediatek,VENC";
			reg = <0x15009000 0x1000>;
			interrupts = <0 138 0x8>;
		};

		VDEC@0x1500B000 {
			compatible = "mediatek,VDEC";
			reg = <0x1500B000 0x1000>;
			interrupts = <0 137 0x8>;
		};

		SMI_LARB1@0x15001000 {
			compatible = "mediatek,SMI_LARB1";
			reg = <0x15001000 0x1000>;
			interrupts = <0 136 0x8>;
		};

		IMGSYS_CONFIG@0x15000000 {
			compatible = "mediatek,IMGSYS_CONFIG";
			reg = <0x15000000 0x1000>;
		};

		hwmsensor@0 {
			compatible = "mediatek,hwmsensor";
		};
		gsensor@0 {
			compatible = "mediatek,gsensor";
		};
		alsps:als_ps@0 {
			compatible = "mediatek,als_ps";
		};
		m_acc_pl@0 {
			compatible = "mediatek,m_acc_pl";
		};
		m_alsps_pl@0 {
			compatible = "mediatek,m_alsps_pl";
		};
		sensorHub@0 {
			compatible = "mediatek,sensorHub";
		};
		shf@0 {
			compatible = "mediatek,shf";
		};
		m_batch_pl@0 {
			compatible = "mediatek,m_batch_pl";
		};
		gyro:gyroscope@0 {
			compatible = "mediatek,gyroscope";
		};
		m_gyro_pl@0 {
			compatible = "mediatek,m_gyro_pl";
		};
		barometer@0 {
			compatible = "mediatek,barometer";
		};
		m_baro_pl@0 {
			compatible = "mediatek,m_baro_pl";
		};
		msensor@0 {
			compatible = "mediatek,msensor";
		};
		m_mag_pl@0 {
			compatible = "mediatek,m_mag_pl";
		};
		orientation@0 {
			compatible = "mediatek,orientation";
		};
		pedometer@0 {
			compatible = "mediatek,pedometer";
		};
		m_pdr_pl@0 {
			compatible = "mediatek,m_pdr_pl";
		};
		step_counter@0 {
			compatible = "mediatek,step_counter";
		};
		m_step_c_pl@0 {
			compatible = "mediatek,m_step_c_pl";
		};
		in_pocket@0 {
			compatible = "mediatek,in_pocket";
		};
		m_inpk_pl@0 {
			compatible = "mediatek,m_inpk_pl";
		};
		shake@0 {
			compatible = "mediatek,shake";
		};
		m_shk_pl@0 {
			compatible = "mediatek,m_shk_pl";
		};
		face_down@0 {
			compatible = "mediatek,face_down";
		};
		m_fdn_pl@0 {
			compatible = "mediatek,m_fdn_pl";
		};
		activity@0 {
			compatible = "mediatek,activity";
		};
		m_act_pl@0 {
			compatible = "mediatek,m_act_pl";
		};
		heart_rate@0 {
			compatible = "mediatek,heart_rate";
		};
		m_hrm_pl@0 {
			compatible = "mediatek,m_hrm_pl";
		};
		tilt_detector@0 {
			compatible = "mediatek,tilt_detector";
		};
		m_tilt_pl@0 {
			compatible = "mediatek,m_tilt_pl";
		};
		wake_gesture@0 {
			compatible = "mediatek,wake_gesture";
		};
		m_wag_pl@0 {
			compatible = "mediatek,m_wag_pl";
		};
		glance_gesture@0 {
			compatible = "mediatek,glance_gesture";
		};
		m_glg_pl@0 {
			compatible = "mediatek,m_glg_pl";
		};
		pick_up@0 {
			compatible = "mediatek,pick_up";
		};
		m_pkup_pl@0 {
			compatible = "mediatek,m_pkup_pl";
		};
		als: als {
			compatible = "mediatek, als-eint";
		};

		mtkfb: mtkfb@0 {
			compatible = "mediatek,mtkfb";
		};

		dsi_te: dsi_te {
			compatible = "mediatek, dsi_te-eint";
		};

	};

	MOBICORE {
		compatible = "trustonic,mobicore";
		interrupts = <0 151 0x1>;
	};
	mt_pmic_regulator {
		compatible = "mediatek,mt_pmic";
		buck_regulators {
			compatible = "mediatek,mt_pmic_buck_regulators";
			mt_pmic_vpa_buck_reg: buck_vpa {
				regulator-name = "vpa";
				regulator-min-microvolt = <500000>;
				regulator-max-microvolt = <3650000>;
				regulator-ramp-delay = <50000>;
				regulator-enable-ramp-delay = <180>;
			};
			mt_pmic_vproc_buck_reg: buck_vproc {
				regulator-name = "vproc";
				regulator-min-microvolt = <700000>;
				regulator-max-microvolt = <1493750>;
				regulator-ramp-delay = <6250>;
				regulator-enable-ramp-delay = <180>;
				regulator-always-on;
				regulator-boot-on;
			};
		};	/* End of buck_regulators */
		ldo_regulators {
			compatible = "mediatek,mt_pmic_ldo_regulators";
			mt_pmic_vcn28_ldo_reg: ldo_vcn28 {
				regulator-name = "vcn28";
				regulator-min-microvolt = <1800000>;
				regulator-max-microvolt = <2800000>;
				regulator-enable-ramp-delay = <264>;
			};
			mt_pmic_vtcxo_ldo_reg: ldo_vtcxo {
				regulator-name = "vtcxo";
				regulator-min-microvolt = <2200000>;
				regulator-max-microvolt = <2200000>;
				regulator-enable-ramp-delay = <110>;
			};
			mt_pmic_va_ldo_reg: ldo_va {
				regulator-name = "va";
				regulator-min-microvolt = <1800000>;
				regulator-max-microvolt = <2500000>;
				regulator-enable-ramp-delay = <110>;
			};
			mt_pmic_vcama_ldo_reg: ldo_vcama {
				regulator-name = "vcama";
				regulator-min-microvolt = <1500000>;
				regulator-max-microvolt = <2800000>;
				regulator-enable-ramp-delay = <264>;
			};
			mt_pmic_vcn33_bt_ldo_reg: ldo_vcn33_bt {
				regulator-name = "vcn33_bt";
				regulator-min-microvolt = <3300000>;
				regulator-max-microvolt = <3600000>;
				regulator-enable-ramp-delay = <264>;
			};
			mt_pmic_vcn33_wifi_ldo_reg: ldo_vcn33_wifi {
				regulator-name = "vcn33_wifi";
				regulator-min-microvolt = <3300000>;
				regulator-max-microvolt = <3600000>;
				regulator-enable-ramp-delay = <264>;
			};
			mt_pmic_vio28_ldo_reg: ldo_vio28 {
				regulator-name = "vio28";
				regulator-min-microvolt = <2800000>;
				regulator-max-microvolt = <2800000>;
				regulator-enable-ramp-delay = <264>;
				regulator-boot-on;
			};
			mt_pmic_vsim1_ldo_reg: ldo_vsim1 {
				regulator-name = "vsim1";
				regulator-min-microvolt = <1800000>;
				regulator-max-microvolt = <3000000>;
				regulator-enable-ramp-delay = <264>;
			};
			mt_pmic_vsim2_ldo_reg: ldo_vsim2 {
				regulator-name = "vsim2";
				regulator-min-microvolt = <1800000>;
				regulator-max-microvolt = <3000000>;
				regulator-enable-ramp-delay = <264>;
			};
			mt_pmic_vusb_ldo_reg: ldo_vusb {
				regulator-name = "vusb";
				regulator-min-microvolt = <3300000>;
				regulator-max-microvolt = <3300000>;
				regulator-enable-ramp-delay = <264>;
				regulator-boot-on;
			};
			mt_pmic_vgp1_ldo_reg: ldo_vgp1 {
				regulator-name = "vgp1";
				regulator-min-microvolt = <1200000>;
				regulator-max-microvolt = <3300000>;
				regulator-enable-ramp-delay = <264>;
			};
			mt_pmic_vgp2_ldo_reg: ldo_vgp2 {
				regulator-name = "vgp2";
				regulator-min-microvolt = <1200000>;
				regulator-max-microvolt = <3000000>;
				regulator-enable-ramp-delay = <264>;
			};
			mt_pmic_vemc_3v3_ldo_reg: ldo_vemc_3v3 {
				regulator-name = "vemc_3v3";
				regulator-min-microvolt = <3000000>;
				regulator-max-microvolt = <3300000>;
				regulator-enable-ramp-delay = <264>;
				regulator-boot-on;
			};
			mt_pmic_vcamaf_ldo_reg: ldo_vcamaf {
				regulator-name = "vcamaf";
				regulator-min-microvolt = <1200000>;
				regulator-max-microvolt = <3300000>;
				regulator-enable-ramp-delay = <264>;
			};
			mt_pmic_vmc_ldo_reg: ldo_vmc {
				regulator-name = "vmc";
				regulator-min-microvolt = <1800000>;
				regulator-max-microvolt = <3300000>;
				regulator-enable-ramp-delay = <44>;
				regulator-boot-on;
			};
			mt_pmic_vmch_ldo_reg: ldo_vmch {
				regulator-name = "vmch";
				regulator-min-microvolt = <3000000>;
				regulator-max-microvolt = <3300000>;
				regulator-enable-ramp-delay = <44>;
				regulator-boot-on;
			};
			mt_pmic_vibr_ldo_reg: ldo_vibr {
				regulator-name = "vibr";
				regulator-min-microvolt = <1200000>;
				regulator-max-microvolt = <3300000>;
				regulator-enable-ramp-delay = <44>;
			};
			mt_pmic_vrtc_ldo_reg: ldo_vrtc {
				regulator-name = "vrtc";
				regulator-min-microvolt = <2800000>;
				regulator-max-microvolt = <2800000>;
				regulator-enable-ramp-delay = <44>;
			};
			mt_pmic_vm_ldo_reg: ldo_vm {
				regulator-name = "vm";
				regulator-min-microvolt = <1200000>;
				regulator-max-microvolt = <1800000>;
				regulator-enable-ramp-delay = <264>;
				regulator-boot-on;
			};
			mt_pmic_vrf18_ldo_reg: ldo_vrf18 {
				regulator-name = "vrf18";
				regulator-min-microvolt = <1800000>;
				regulator-max-microvolt = <1800000>;
				regulator-enable-ramp-delay = <220>;
			};
			mt_pmic_vio18_ldo_reg: ldo_vio18 {
				regulator-name = "vio18";
				regulator-min-microvolt = <1800000>;
				regulator-max-microvolt = <1800000>;
				regulator-enable-ramp-delay = <264>;
				regulator-boot-on;
			};
			mt_pmic_vcamd_ldo_reg: ldo_vcamd {
				regulator-name = "vcamd";
				regulator-min-microvolt = <1200000>;
				regulator-max-microvolt = <1800000>;
				regulator-enable-ramp-delay = <264>;
			};
			mt_pmic_vcamio_ldo_reg: ldo_vcamio {
				regulator-name = "vcamio";
				regulator-min-microvolt = <1800000>;
				regulator-max-microvolt = <1800000>;
				regulator-enable-ramp-delay = <220>;
			};
			mt_pmic_vgp3_ldo_reg: ldo_vgp3 {
				regulator-name = "vgp3";
				regulator-min-microvolt = <1200000>;
				regulator-max-microvolt = <1800000>;
				regulator-enable-ramp-delay = <264>;
			};
			mt_pmic_vcn_1v8_ldo_reg: ldo_vcn_1v8 {
			regulator-name = "vcn_1v8";
				regulator-min-microvolt = <1800000>;
				regulator-max-microvolt = <1800000>;
				regulator-enable-ramp-delay = <44>;
			};

			mt_pmic_vcanio_ldo_reg:vcanio_ldo_reg {
			};
			mt_pmic_vcn33_ldo_reg:vcn33_ldo_reg {
			};
		};/* End of ldo_regulators */
		regulators_supply {
			compatible = "mediatek,mt_pmic_regulator_supply";
			vcn28-supply = <&mt_pmic_vcn28_ldo_reg>;
			vtcxo-supply = <&mt_pmic_vtcxo_ldo_reg>;
			va-supply = <&mt_pmic_va_ldo_reg>;
			vcn33_bt-supply = <&mt_pmic_vcn33_bt_ldo_reg>;
			vcn33_wifi-supply = <&mt_pmic_vcn33_wifi_ldo_reg>;
			vio28-supply = <&mt_pmic_vio28_ldo_reg>;
			vsim1-supply = <&mt_pmic_vsim1_ldo_reg>;
			vsim2-supply = <&mt_pmic_vsim2_ldo_reg>;
			vusb-supply = <&mt_pmic_vusb_ldo_reg>;
			vgp1-supply = <&mt_pmic_vgp1_ldo_reg>;
			vgp2-supply = <&mt_pmic_vgp2_ldo_reg>;
			vemc_3v3-supply = <&mt_pmic_vemc_3v3_ldo_reg>;
			vcamaf-supply = <&mt_pmic_vcamaf_ldo_reg>;
			vmc-supply = <&mt_pmic_vmc_ldo_reg>;
			vmch-supply = <&mt_pmic_vmch_ldo_reg>;
			vibr-supply = <&mt_pmic_vibr_ldo_reg>;
			vrtc-supply = <&mt_pmic_vrtc_ldo_reg>;
			vm-supply = <&mt_pmic_vm_ldo_reg>;
			vrf18-supply = <&mt_pmic_vrf18_ldo_reg>;
			vio18-supply = <&mt_pmic_vio18_ldo_reg>;
			vcamd-supply = <&mt_pmic_vcamd_ldo_reg>;
			vcamio-supply = <&mt_pmic_vcamio_ldo_reg>;
			vgp3-supply = <&mt_pmic_vgp3_ldo_reg>;
			vcn_1v8-supply = <&mt_pmic_vcn_1v8_ldo_reg>;
		};/* End of regulators_supply */
	};/* End of mt_pmic_regulator */

	rf_clock_buffer_ctrl:rf_clock_buffer {
		compatible = "mediatek,rf_clock_buffer";
		#mediatek,clkbuf-quantity = <4>;
		#mediatek,clkbuf-config = <2 1 1 1>;
	};

};

#include <cust.dtsi>
#include <trusty.dtsi>

&eintc {
	pmic@13 {
		compatible = "mediatek, pmic-eint";
		interrupt-parent = <&eintc>;
		interrupts = <13 4>;
		debounce = <13 1000>;
	};
};
